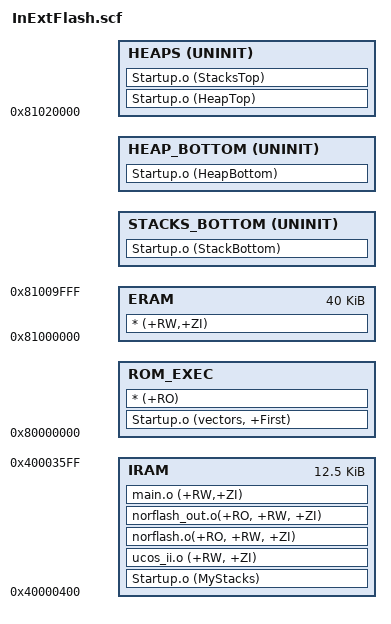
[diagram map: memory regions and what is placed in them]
;/****************************************Copyright (c)****************************************************
;**                  Beijing TIANDI-MARCO Electro-Hydraulic Control System CO.,LTD.
;**                                      
;**                                 http://www.tdmarco.com
;**
;**--------------File Info---------------------------------------------------------------------------------
;** File Name:              RelOutChip.scf
;** Last modified Date:     2010-12-14
;** Last Version:           1.0
;** Descriptions:           Scatter File
;**
;**------------------------------------------------------------------------------------------------------
;** Created By:             Lijianming
;** Created date:           2010-12-14
;** Version:                1.0
;** Descriptions:           First version
;**
;**------------------------------------------------------------------------------------------------------
;** Modified by:            
;** Modified date:          
;** Version:                
;** Descriptions:          
;**   
;********************************************************************************************************/
ROM_LOAD 0x80000000
{
    ROM_EXEC 0x80000000
    {
        Startup.o (vectors, +First)
        * (+RO)
    } 
	
    IRAM 0x40000400  0x3200                                                   ;/*  默认MCU具有内部RAM         */
    {
        Startup.o (MyStacks)
        ;oled.o (+RW,+ZI)
        ucos_ii.o (+RW, +ZI)
        norflash.o(+RO, +RW, +ZI)
        norflash_out.o(+RO, +RW, +ZI)
        main.o (+RW,+ZI)
    }
    
    ERAM 0x81000000 0xA000                                                    ;/*  外扩RAM默认在BANK1         */
    {
        * (+RW,+ZI)
    }
    
    STACKS_BOTTOM +0 UNINIT ;0x40003700
    {
        Startup.o (StackBottom)
    }
  
    HEAP_BOTTOM +0 UNINIT
    {
        Startup.o (HeapBottom)
    }

    HEAPS 0x81020000 UNINIT                                             ;/*  根据外扩RAM实际大小更改    */
    {
        Startup.o (HeapTop)
        Startup.o (StacksTop)
    }

 }

;********************************************************************************************************/
